# apollo1 register map
Vendor: Ambiq Micro, Inc.; Series: Apollo; File version: 1.0
CPU: CM4 r1p0, little endian, MPU, FPU, 3 interrupt priority bits
Registers are 32-bit, read-write, reset 0x0 unless marked. A register's access mark holds for its fields unless they carry their own. Offsets are from the block's base; [hi:lo] are bit positions; {n}, {i} and the like mark numbered series; 'fields as' and 'values as' point back to an identical list.

## CLKGEN — Clock Generator
Base 0x40004000
0x00 CALXT — XT Oscillator Control
  [10:0] CALXT — XT Oscillator calibration value
0x04 CALRC — RC Oscillator Control
  [17:0] CALRC — LFRC Oscillator calibration value
0x08 ACALCTR — Autocalibration Counter
  [23:0] ACALCTR — Autocalibration Counter result.
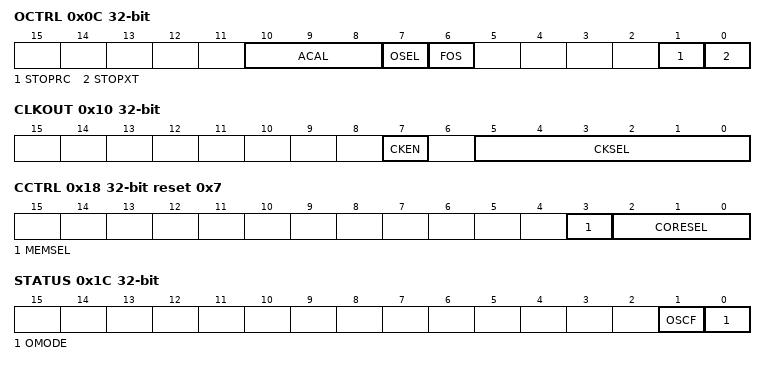
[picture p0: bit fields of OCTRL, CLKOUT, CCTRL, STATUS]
0x0C OCTRL — Oscillator Control
  [10:8] ACAL — Autocalibration control
    0=DIS (Disable Autocalibration); 2=1024SEC (Autocalibrate every 1024 seconds); 3=512SEC (Autocalibrate every 512 seconds); 6=XTFREQ (Frequency measurement using XT); 7=EXTFREQ (Frequency measurement using external clock)
  [7] OSEL — Selects the RTC oscillator (1 => LFRC, 0 => XT)
    0=RTC_XT (RTC uses the XT); 1=RTC_LFRC (RTC uses the LFRC)
  [6] FOS — Oscillator switch on failure function
    0=DIS (Disable the oscillator switch on failure function); 1=EN (Enable the oscillator switch on failure function)
  [1] STOPRC — Stop the LFRC Oscillator to the RTC
    0=EN (Enable the LFRC Oscillator to drive the RTC); 1=STOP (Stop the LFRC Oscillator when driving the RTC)
  [0] STOPXT — Stop the XT Oscillator to the RTC
    0=EN (Enable the XT Oscillator to drive the RTC); 1=STOP (Stop the XT Oscillator when driving the RTC)
0x10 CLKOUT — CLKOUT Frequency Select
  [7] CKEN — Enable the CLKOUT signal
    0=DIS (Disable CLKOUT); 1=EN (Enable CLKOUT)
  [5:0] CKSEL — CLKOUT signal select
    0=LFRC; 1=XT_DIV2 (XT / 2); 2=XT_DIV4 (XT / 4); 3=XT_DIV8 (XT / 8); 4=XT_DIV16 (XT / 16); 5=XT_DIV32 (XT / 32); 16=RTC_1Hz (1 Hz as selected in RTC); 22=XT_DIV2M (XT / 2^21); 23=XT; 24=CG_100Hz (100 Hz as selected in CLKGEN); 25=HFRC; 26=HFRC_DIV2 (HFRC / 2); 27=HFRC_DIV4 (HFRC / 4); 28=HFRC_DIV8 (HFRC / 8); 29=HFRC_DIV32 (HFRC / 32); 30=HFRC_DIV64 (HFRC / 64); 31=HFRC_DIV128 (HFRC / 128); 32=HFRC_DIV256 (HFRC / 256); 34=FLASH_CLK (Flash Clock); 35=LFRC_DIV2 (LFRC / 2); 36=LFRC_DIV32 (LFRC / 32); 37=LFRC_DIV512 (LFRC / 512); 38=LFRC_DIV32K (LFRC / 32768); 39=XT_DIV256 (XT / 256); 40=XT_DIV8K (XT / 8192); 41=XT_DIV64K (XT / 2^16); 42=ULFRC_DIV16 (Uncal LFRC / 16); 43=ULFRC_DIV128 (Uncal LFRC / 128); 44=ULFRC_1Hz (Uncal LFRC / 1024); 45=ULFRC_DIV4K (Uncal LFRC / 4096); 46=ULFRC_DIV1M (Uncal LFRC / 2^20); 47=HFRC_DIV64K (HFRC / 2^16); 48=HFRC_DIV16M (HFRC / 2^24); 49=LFRC_DIV2M (LFRC / 2^20); 50=HFRCNE (HFRC (not autoenabled)); 51=HFRCNE_DIV8 (HFRC / 8 (not autoenabled)); 53=XTNE (XT (not autoenabled)); 54=XTNE_DIV16 (XT / 16 (not autoenabled)); 55=LFRCNE_DIV32 (LFRC / 32 (not autoenabled)); 57=LFRCNE (LFRC (not autoenabled) - Default for undefined values)
0x14 CLKKEY — Key Register for Clock Control Register
  [31:0] CLKKEY — Key register value.
    71=Key
0x18 CCTRL reset 0x7 — HFRC Clock Control
  [3] MEMSEL — Flash Clock divisor
    0=HFRC_DIV25 (Flash Clock is HFRC / 25); 1=HFRC_DIV45 (Flash Clock is HFRC / 45)
  [2:0] CORESEL — Core Clock divisor
    0=HFRC (Core Clock is HFRC); {v}=HFRC_DIV{v+1} (Core Clock is HFRC / {v+1}) (v=1..7)
0x1C STATUS — Clock Generator Status
  [1] OSCF — XT Oscillator is enabled but not oscillating
  [0] OMODE — Current RTC oscillator (1 => LFRC, 0 => XT)
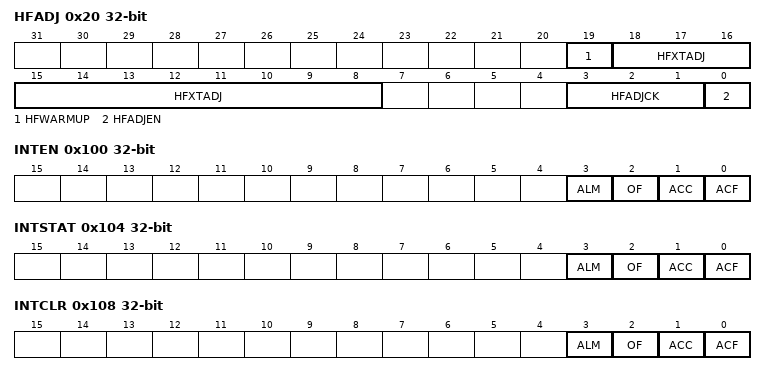
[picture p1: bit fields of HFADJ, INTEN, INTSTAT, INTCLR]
0x20 HFADJ — HFRC Adjustment
  [19] HFWARMUP — XT warmup period for HFRC adjustment
    0=1SEC (Autoadjust XT warmup period = 1-2 seconds); 1=2SEC (Autoadjust XT warmup period = 2-4 seconds)
  [18:8] HFXTADJ — Target HFRC adjustment value.
  [3:1] HFADJCK — Repeat period for HFRC adjustment
    0=4SEC (Autoadjust repeat period = 4 seconds); 1=16SEC (Autoadjust repeat period = 16 seconds); 2=32SEC (Autoadjust repeat period = 32 seconds); 3=64SEC (Autoadjust repeat period = 64 seconds); 4=128SEC (Autoadjust repeat period = 128 seconds); 5=256SEC (Autoadjust repeat period = 256 seconds); 6=512SEC (Autoadjust repeat period = 512 seconds); 7=1024SEC (Autoadjust repeat period = 1024 seconds)
  [0] HFADJEN — HFRC adjustment control
    0=DIS (Disable the HFRC adjustment); 1=EN (Enable the HFRC adjustment)
0x24 HFVAL — HFADJ readback
  [10:0] HFTUNERB — Current HFTUNE value
0x28 CLOCKEN — Clock Enable Status
  [31:0] CLOCKEN — Clock enable status
0x2C UARTEN — UART Enable
  [0] UARTEN — UART system clock control
    0=DIS (Disable the UART system clock); 1=EN (Enable the UART system clock)
0x100 INTEN — CLKGEN Interrupt Register: Enable
  [3] ALM — RTC Alarm interrupt
  [2] OF — XT Oscillator Fail interrupt
  [1] ACC — Autocalibration Complete interrupt
  [0] ACF — Autocalibration Fail interrupt
0x104 INTSTAT — CLKGEN Interrupt Register: Status
  fields as INTEN
0x108 INTCLR — CLKGEN Interrupt Register: Clear
  fields as INTEN
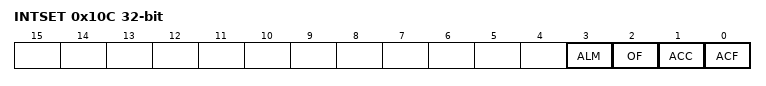
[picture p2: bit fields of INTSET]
0x10C INTSET — CLKGEN Interrupt Register: Set
  fields as INTEN
